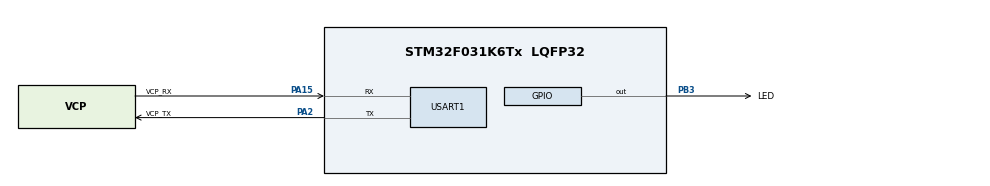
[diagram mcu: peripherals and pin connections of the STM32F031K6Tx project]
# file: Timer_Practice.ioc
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Mcu.Family=STM32F0
PA14.GPIO_Label=SWCLK
VP_TIM16_VS_ClockSourceINT.Mode=Enable_Timer
ProjectManager.StackSize=0x400
USART1.VirtualMode-Asynchronous=VM_ASYNC
PA13.Signal=SYS_SWDIO
PA15.GPIO_Label=VCP_RX
ProjectManager.TargetToolchain=STM32CubeIDE
PF0-OSC_IN.Mode=HSE-External-Clock-Source
board=NUCLEO-F031K6
PA15.Mode=Asynchronous
VP_TIM2_VS_ClockSourceINT.Mode=Internal
PA14.Mode=Serial_Wire
PA13.Mode=Serial_Wire
Mcu.Name=STM32F031K6Tx
PA2.Signal=USART1_TX
PA13.GPIO_Label=SWDIO
PB3.Signal=GPIO_Output
Mcu.Package=LQFP32
TIM2.Prescaler=8-1
PA2.GPIO_Label=VCP_TX
PA14.Signal=SYS_SWCLK
PA15.Signal=USART1_RX
ProjectManager.HeapSize=0x200
PA2.Mode=Asynchronous
TIM16.Prescaler=800-1
PF0-OSC_IN.Signal=RCC_OSC_IN
PB3.GPIO_Label=LED

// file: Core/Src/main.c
/* USER CODE BEGIN Header */
/**
  ******************************************************************************
  * @file           : main.c
  * @brief          : Main program body
  ******************************************************************************
  * @attention
  *
  * <h2><center>&copy; Copyright (c) 2021 STMicroelectronics.
  * All rights reserved.</center></h2>
  *
  * This software component is licensed by ST under BSD 3-Clause license,
  * the "License"; You may not use this file except in compliance with the
  * License. You may obtain a copy of the License at:
  *                        opensource.org/licenses/BSD-3-Clause
  *
  ******************************************************************************
  */
/* USER CODE END Header */
#include "main.h"

TIM_HandleTypeDef htim2;
TIM_HandleTypeDef htim16;

UART_HandleTypeDef huart1;

void SystemClock_Config(void);
static void MX_GPIO_Init(void);
static void MX_USART1_UART_Init(void);
static void MX_TIM16_Init(void);
static void MX_TIM2_Init(void);

int main(void)
{
  /* USER CODE BEGIN 1 */
	char uart_buf[50];
	int uart_buf_len;
	uint16_t timer_val;

  /* USER CODE END 1 */

  /* MCU Configuration--------------------------------------------------------*/

  /* Reset of all peripherals, Initializes the Flash interface and the Systick. */
  HAL_Init();

  /* Configure the system clock */
  SystemClock_Config();

  /* Initialize all configured peripherals */
  MX_GPIO_Init();
  MX_USART1_UART_Init();
  MX_TIM16_Init();
  MX_TIM2_Init();
  /* USER CODE BEGIN 2 */

  /* Timer 2
   * - Set to 1Mhz
   * - 32 bit count to 4294967295 in mode UP
   */

  // Say hello
  uart_buf_len = sprintf(uart_buf, "Timer test program started!\r\n");
  HAL_UART_Transmit(&huart1, (uint8_t *)uart_buf, uart_buf_len, 100);

  //Start the timer
  HAL_TIM_Base_Start(&htim2);

  /* USER CODE END 2 */

  /* Infinite loop */
  while (1)
  {

    /* USER CODE BEGIN 3 */

	  //Get start time
	  timer_val = __HAL_TIM_GET_COUNTER(&htim2);

	  //Program execute
	  //HAL_GPIO_TogglePin(GPIOB, GPIO_PIN_3);
	  HAL_Delay(25);

	  //Elapsed Time
	  timer_val = __HAL_TIM_GET_COUNTER(&htim2) - timer_val;

	  //Print elapsed time to UART
	  uart_buf_len = sprintf(uart_buf, "Duration: %u us\r\n", timer_val);
      HAL_UART_Transmit(&huart1, (uint8_t *)uart_buf, uart_buf_len, 100);

  }
  /* USER CODE END 3 */
}

void SystemClock_Config(void)
{
  RCC_OscInitTypeDef RCC_OscInitStruct = {0};
  RCC_ClkInitTypeDef RCC_ClkInitStruct = {0};
  RCC_PeriphCLKInitTypeDef PeriphClkInit = {0};

  /** Initializes the RCC Oscillators according to the specified parameters
  * in the RCC_OscInitTypeDef structure.
  */
  RCC_OscInitStruct.OscillatorType = RCC_OSCILLATORTYPE_HSI;
  RCC_OscInitStruct.HSIState = RCC_HSI_ON;
  RCC_OscInitStruct.HSICalibrationValue = RCC_HSICALIBRATION_DEFAULT;
  RCC_OscInitStruct.PLL.PLLState = RCC_PLL_NONE;
  if (HAL_RCC_OscConfig(&RCC_OscInitStruct) != HAL_OK)
  {
    Error_Handler();
  }
  /** Initializes the CPU, AHB and APB buses clocks
  */
  RCC_ClkInitStruct.ClockType = RCC_CLOCKTYPE_HCLK|RCC_CLOCKTYPE_SYSCLK
                              |RCC_CLOCKTYPE_PCLK1;
  RCC_ClkInitStruct.SYSCLKSource = RCC_SYSCLKSOURCE_HSI;
  RCC_ClkInitStruct.AHBCLKDivider = RCC_SYSCLK_DIV1;
  RCC_ClkInitStruct.APB1CLKDivider = RCC_HCLK_DIV1;

  if (HAL_RCC_ClockConfig(&RCC_ClkInitStruct, FLASH_LATENCY_0) != HAL_OK)
  {
    Error_Handler();
  }
  PeriphClkInit.PeriphClockSelection = RCC_PERIPHCLK_USART1;
  PeriphClkInit.Usart1ClockSelection = RCC_USART1CLKSOURCE_PCLK1;
  if (HAL_RCCEx_PeriphCLKConfig(&PeriphClkInit) != HAL_OK)
  {
    Error_Handler();
  }
}

static void MX_TIM2_Init(void)
{

  TIM_ClockConfigTypeDef sClockSourceConfig = {0};
  TIM_MasterConfigTypeDef sMasterConfig = {0};

  htim2.Instance = TIM2;
  htim2.Init.Prescaler = 8-1;
  htim2.Init.CounterMode = TIM_COUNTERMODE_UP;
  htim2.Init.Period = 4294967295;
  htim2.Init.ClockDivision = TIM_CLOCKDIVISION_DIV1;
  htim2.Init.AutoReloadPreload = TIM_AUTORELOAD_PRELOAD_DISABLE;
  if (HAL_TIM_Base_Init(&htim2) != HAL_OK)
  {
    Error_Handler();
  }
  sClockSourceConfig.ClockSource = TIM_CLOCKSOURCE_INTERNAL;
  if (HAL_TIM_ConfigClockSource(&htim2, &sClockSourceConfig) != HAL_OK)
  {
    Error_Handler();
  }
  sMasterConfig.MasterOutputTrigger = TIM_TRGO_RESET;
  sMasterConfig.MasterSlaveMode = TIM_MASTERSLAVEMODE_DISABLE;
  if (HAL_TIMEx_MasterConfigSynchronization(&htim2, &sMasterConfig) != HAL_OK)
  {
    Error_Handler();
  }

}

static void MX_TIM16_Init(void)
{

  htim16.Instance = TIM16;
  htim16.Init.Prescaler = 8-1;
  htim16.Init.CounterMode = TIM_COUNTERMODE_UP;
  htim16.Init.Period = 65535;
  htim16.Init.ClockDivision = TIM_CLOCKDIVISION_DIV1;
  htim16.Init.RepetitionCounter = 0;
  htim16.Init.AutoReloadPreload = TIM_AUTORELOAD_PRELOAD_DISABLE;
  if (HAL_TIM_Base_Init(&htim16) != HAL_OK)
  {
    Error_Handler();
  }

}

static void MX_USART1_UART_Init(void)
{

  huart1.Instance = USART1;
  huart1.Init.BaudRate = 38400;
  huart1.Init.WordLength = UART_WORDLENGTH_8B;
  huart1.Init.StopBits = UART_STOPBITS_1;
  huart1.Init.Parity = UART_PARITY_NONE;
  huart1.Init.Mode = UART_MODE_TX_RX;
  huart1.Init.HwFlowCtl = UART_HWCONTROL_NONE;
  huart1.Init.OverSampling = UART_OVERSAMPLING_16;
  huart1.Init.OneBitSampling = UART_ONE_BIT_SAMPLE_DISABLE;
  huart1.AdvancedInit.AdvFeatureInit = UART_ADVFEATURE_NO_INIT;
  if (HAL_UART_Init(&huart1) != HAL_OK)
  {
    Error_Handler();
  }

}

static void MX_GPIO_Init(void)
{
  GPIO_InitTypeDef GPIO_InitStruct = {0};

  /* GPIO Ports Clock Enable */
  __HAL_RCC_GPIOF_CLK_ENABLE();
  __HAL_RCC_GPIOA_CLK_ENABLE();
  __HAL_RCC_GPIOB_CLK_ENABLE();

  /*Configure GPIO pin Output Level */
  HAL_GPIO_WritePin(LED_GPIO_Port, LED_Pin, GPIO_PIN_RESET);

  /*Configure GPIO pin : LED_Pin */
  GPIO_InitStruct.Pin = LED_Pin;
  GPIO_InitStruct.Mode = GPIO_MODE_OUTPUT_PP;
  GPIO_InitStruct.Pull = GPIO_NOPULL;
  GPIO_InitStruct.Speed = GPIO_SPEED_FREQ_LOW;
  HAL_GPIO_Init(LED_GPIO_Port, &GPIO_InitStruct);

}

void Error_Handler(void)
{
  __disable_irq();
  while (1)
  {
  }
}

/************************ (C) COPYRIGHT STMicroelectronics *****END OF FILE****/
